# R7FS3A17 register map
Vendor: Renesas; Series: S3; File version: 1.2
CPU: CM4 r0p1, little endian, MPU, FPU, VTOR, 4 interrupt priority bits
Registers are 8-bit, read-write, reset 0x0 unless marked. A register's access mark holds for its fields unless they carry their own. Offsets are from the block's base; [hi:lo] are bit positions; {n}, {i} and the like mark numbered series.

## GPT_OPS — Output Phase Switching Controller
Base 0x40078FF0
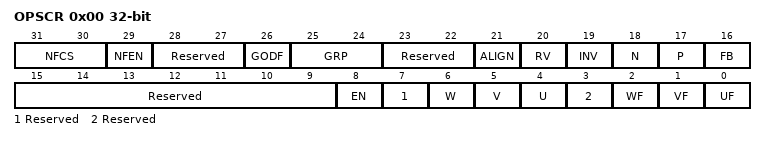
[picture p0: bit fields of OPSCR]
0x00 OPSCR 32-bit — Output Phase Switching Control Register
  [31:30] NFCS — External Input Noise Filter Clock selection Noise filter sampling clock setting of the external input.
    0=PCLK/1; 1=PCLK/4; 2=PCLK/16; 3=PCLK/64
  [29] NFEN — External Input Noise Filter Enable
    0=Do not use a noise filter to the external input; 1=Use a noise filter to the external input
  [28:27] Reserved — These bits are read as 00. The write value should be 00.
  [26] GODF — Group output disable function
    0=This bit function is ignored; 1=Group disable will clear OPSCR.EN Bit
  [25:24] GRP — Output disabled source selection
    0=Select Group A output disable source; 1=Select Group B output disable source; other=others (Setting prohibited)
  [23:22] Reserved — These bits are read as 00. The write value should be 00.
  [21] ALIGN — Input phase alignment
    0=Input phase is aligned to PCLK; 1=Input phase is aligned PWM
  [20] RV — Output phase rotation direction reversal
    0=U/V/W-Phase output; 1=Output to reverse the V / W-phase
  [19] INV — Invert-Phase Output Control
    0=Positive Logic (Active High)output; 1=Negative Logic (Active Low)output
  [18] N — Negative-Phase Output (N) Control
    0=Level signal output; 1=PWM signal output (PWM of GPT0)
  [17] P — Positive-Phase Output (P) Control
    0=Level signal output; 1=PWM signal output (PWM of GPT0)
  [16] FB — External Feedback Signal Enable This bit selects the input phase from the software settings and external input.
    0=Select the external input; 1=Select the soft setting(OPSCR.UF, VF, WF)
  [15:9] Reserved — These bits are read as 0000000. The write value should be 0000000.
  [8] EN — Enable-Phase Output Control
    0=Not Output(Hi-Z external terminals); 1=Output
  [7] Reserved — This bit is read as 0. The write value should be 0.
  [6] W ro — Input W-Phase Monitor This bit monitors the state of the input phase. OPSCR.FB=0:External input monitoring by PCLK OPSCR.FB=1:Software settings (UF/VF/WF)
  [5] V ro — Input V-Phase Monitor This bit monitors the state of the input phase. OPSCR.FB=0:External input monitoring by PCLK OPSCR.FB=1:Software settings (UF/VF/WF)
  [4] U ro — Input U-Phase Monitor This bit monitors the state of the input phase. OPSCR.FB=0:External input monitoring by PCLK OPSCR.FB=1:Software settings (UF/VF/WF)
  [3] Reserved — This bit is read as 0. The write value should be 0.
  [2] WF — Input Phase Soft Setting UF This bit sets the input phase by the software settings. This bit setting is valid when the OPSCR.FB bit = 1.
  [1] VF — Input Phase Soft Setting VF This bit sets the input phase by the software settings. This bit setting is valid when the OPSCR.FB bit = 1.
  [0] UF — Input Phase Soft Setting WF This bit sets the input phase by the software settings. This bit setting is valid when the OPSCR.FB bit = 1.

## POEG — Port Output Enable Module for GPT
Base 0x40042000
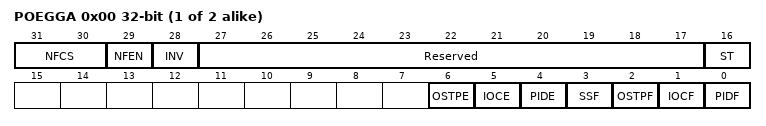
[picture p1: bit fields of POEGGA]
0x00 POEGG{x} (x=A,B; step 0x100) 32-bit — POEG Group {x} Setting Register
  [31:30] NFCS — Noise Filter Clock Select
    0=Sampling GTETRG pin input level for three times in every PCLKB; 1=Sampling GTETRG pin input level for three times in every PCLKB /8; 2=Sampling GTETRG pin input level for three times in every PCLKB /32; 3=Sampling GTETRG pin input level for three times in every PCLKB /128
  [29] NFEN — Noise Filter Enable
    0=Filtering noise disabled; 1=Filtering noise enabled
  [28] INV — GTETRG Input Reverse
    0=GTETRG Input; 1=GTETRG Input Reversed
  [27:17] Reserved — These bits are read as 00000000000. The write value should be 00000000000.
  [16] ST ro — GTETRG Input Status Flag
    0=GTETRG input after filtering is 0; 1=GTETRG input after filtering is 1
  [6] OSTPE — Oscillation Stop Detection Enable Note: Can be modified only once after a reset.
    0=A output-disable request from the oscillation stop detection disabled; 1=A output-disable request from the oscillation stop detection enabled
  [5] IOCE — Output-disable Request Enable from GPT Note: Can be modified only once after a reset.
    0=Output-disable request from the GPT disable request disabled; 1=Output-disable request from the GPT disable request enabled
  [4] PIDE — Port Input Detection Enable Note: Can be modified only once after a reset.
    0=Output-disable request from the GTETRG pins disabled; 1=Output-disable request from the GTETRG pins enabled
  [3] SSF — Software Stop Flag
    0=No output-disable request from software has occurred; 1=Output-disable request from software occurred
  [2] OSTPF write-0-clears read-modifies — Oscillation Stop Detection Flag
    0=No output-disable request from oscillation stop detection has occurred; 1=Output-disable request from oscillation stop detection occurred
  [1] IOCF write-0-clears read-modifies — Output-disable Request Detection Flag from GPT
    0=No output-disable request from the GPT disable request has occurred; 1=Output-disable request from the GPT disable request occurred
  [0] PIDF write-0-clears read-modifies — Port Input Detection Flag
    0=No output-disable request from the GTETRGn pin has occurred; 1=Output-disable request from the GTETRGn pin occurred
